# PIC32CM5164JH00032 register map
Vendor: Microchip Technology; Series: PIC32CMJH00; File version: 0
CPU: CM0+ r0p0, little endian, MPU, no FPU, VTOR, 2 interrupt priority bits, 32 interrupts
Registers are 32-bit, read-write, reset 0x0 unless marked. A register's access mark holds for its fields unless they carry their own. Offsets are from the block's base; [hi:lo] are bit positions; {n}, {i} and the like mark numbered series; 'fields as' and 'values as' point back to an identical list.

## OSCCTRL — Oscillators Control
Base 0x40001000
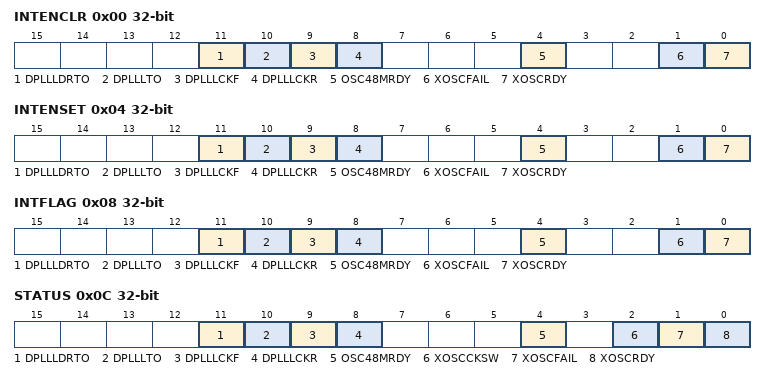
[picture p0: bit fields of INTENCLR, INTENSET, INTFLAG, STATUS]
0x00 INTENCLR write-1-clears — Interrupt Enable Clear
  [11] DPLLLDRTO — DPLL Ratio Ready Interrupt Enable
  [10] DPLLLTO — DPLL Time Out Interrupt Enable
  [9] DPLLLCKF — DPLL Lock Fall Interrupt Enable
  [8] DPLLLCKR — DPLL Lock Rise Interrupt Enable
  [4] OSC48MRDY — OSC48M Ready Interrupt Enable
  [1] XOSCFAIL — XOSC Clock Failure Detector Interrupt Enable
  [0] XOSCRDY — XOSC Ready Interrupt Enable
0x04 INTENSET write-1-sets — Interrupt Enable Set
  fields as INTENCLR
0x08 INTFLAG write-1-clears — Interrupt Flag Status and Clear
  [11] DPLLLDRTO — DPLL Ratio Ready
  [10] DPLLLTO — DPLL Timeout
  [9] DPLLLCKF — DPLL Lock Fall
  [8] DPLLLCKR — DPLL Lock Rise
  [4] OSC48MRDY — OSC48M Ready
  [1] XOSCFAIL — XOSC Clock Failure Detector
  [0] XOSCRDY — XOSC Ready
0x0C STATUS ro — Power and Clocks Status
  [11] DPLLLDRTO — DPLL Ratio Ready
  [10] DPLLLTO — DPLL Timeout
  [9] DPLLLCKF — DPLL Lock Fall
  [8] DPLLLCKR — DPLL Lock Rise
  [4] OSC48MRDY — OSC48M Ready
  [2] XOSCCKSW — XOSC Clock Switch
  [1] XOSCFAIL — XOSC Clock Failure Detector
  [0] XOSCRDY — XOSC Ready
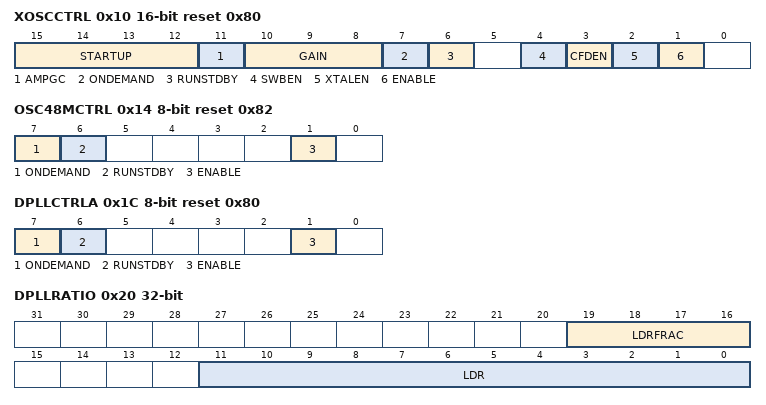
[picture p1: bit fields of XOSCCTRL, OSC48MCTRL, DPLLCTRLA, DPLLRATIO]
0x10 XOSCCTRL 16-bit reset 0x80 — External Multipurpose Crystal Oscillator (XOSC) Control
  [15:12] STARTUP — Start-Up Time
    0=CYCLE1 (1 cycle); 1=CYCLE2 (2 cycles); 2=CYCLE4 (4 cycles); 3=CYCLE8 (8 cycles); 4=CYCLE16 (16 cycles); 5=CYCLE32 (32 cycles); 6=CYCLE64 (64 cycles); 7=CYCLE128 (128 cycles); 8=CYCLE256 (256 cycles); 9=CYCLE512 (512 cycles); 10=CYCLE1024 (1024 cycles); 11=CYCLE2048 (2048 cycles); 12=CYCLE4096 (4096 cycles); 13=CYCLE8192 (8192 cycles); 14=CYCLE16384 (16384 cycles); 15=CYCLE32768 (32768 cycles)
  [11] AMPGC — Automatic Amplitude Gain Control
  [10:8] GAIN — Oscillator Gain
    0=2 MHz; 1=4 MHz; 2=8 MHz; 3=16 MHz; 4=32 MHz
  [7] ONDEMAND — On Demand Control
  [6] RUNSTDBY — Run in Standby
  [4] SWBEN — Clock Switch Back Enable
  [3] CFDEN — Xosc Clock Failure Detector Enable
  [2] XTALEN — Crystal Oscillator Enable
  [1] ENABLE — Oscillator Enable
0x12 CFDPRESC 8-bit — Clock Failure Detector Prescaler
  [2:0] CFDPRESC
    0=DIV1 (OSC48M frequency); 1=DIV2 (OSC48M frequency / 2); 2=DIV4 (OSC48M frequency / 4); 3=DIV8 (OSC48M frequency / 8); 4=DIV16 (OSC48M frequency / 16); 5=DIV32 (OSC48M frequency / 32); 6=DIV64 (OSC48M frequency / 64); 7=DIV128 (OSC48M frequency / 128)
0x13 EVCTRL 8-bit — Event Control
  [0] CFDEO — Clock Failure Detector Event Output Enable
0x14 OSC48MCTRL 8-bit reset 0x82 — 48MHz Internal Oscillator (OSC48M) Control
  [7] ONDEMAND — On Demand Control
  [6] RUNSTDBY — Run in Standby
  [1] ENABLE — Oscillator Enable
0x15 OSC48MDIV 8-bit reset 0xB — OSC48M Divider
  [3:0] DIV — OSC48M Division Factor
    0=48 MHz; 1=24 MHz; 2=16 MHz; 3=12 MHz; 4=9.6 MHz; 5=8 MHz; 6=6.86 MHz; 7=6 MHz; 8=5.33 MHz; 9=4.8 MHz; 10=4.36 MHz; 11=4 MHz; 12=3.69 MHz; 13=3.43 MHz; 14=3.2 MHz; 15=3 MHz
0x16 OSC48MSTUP 8-bit reset 0x7 — OSC48M Startup Time
  [2:0] STARTUP — Startup Time
    0=CYCLE8 (166 ns); 1=CYCLE16 (333 ns); 2=CYCLE32 (667 ns); 3=CYCLE64 (1.333 us); 4=CYCLE128 (2.667 us); 5=CYCLE256 (5.333 us); 6=CYCLE512 (10.667 us); 7=CYCLE1024 (21.333 us)
0x18 OSC48MSYNCBUSY ro — OSC48M Synchronization Busy
  [2] OSC48MDIV — OSC48MDIV Synchronization Status
0x1C DPLLCTRLA 8-bit reset 0x80 — DPLL Control
  [7] ONDEMAND
  [6] RUNSTDBY — Run in Standby
  [1] ENABLE
0x20 DPLLRATIO — DPLL Ratio Control
  [19:16] LDRFRAC — Loop Divider Ratio Fractional Part
  [11:0] LDR — Loop Divider Ratio
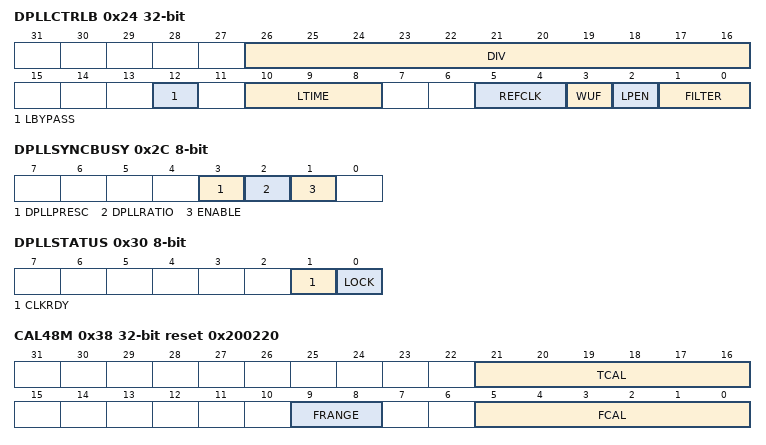
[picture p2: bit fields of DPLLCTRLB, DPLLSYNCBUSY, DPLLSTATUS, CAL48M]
0x24 DPLLCTRLB — Digital Core Configuration
  [26:16] DIV — Clock Divider
  [12] LBYPASS — Lock Bypass
  [10:8] LTIME — Lock Time
    0=Default (No time-out. Automatic lock); {v}={v+4}MS (Time-out if no lock within {v+4} ms) (v=4..7)
  [5:4] REFCLK — Reference Clock Selection
    0=XOSC32K (XOSC32K Clock Reference); 1=XOSC (XOSC Clock Reference); 2=GCLK (GCLK Clock Reference)
  [3] WUF — Wake Up Fast
  [2] LPEN — Low-Power Enable
  [1:0] FILTER — Proportional Integral Filter Selection
    0=Default Filter Mode; 1=LBFILT (Low Bandwidth Filter); 2=HBFILT (High Bandwidth Filter); 3=HDFILT (High Damping Filter)
0x28 DPLLPRESC 8-bit — DPLL Prescaler
  [1:0] PRESC — Output Clock Prescaler
    0=DIV1 (DPLL output is divided by 1); 1=DIV2 (DPLL output is divided by 2); 2=DIV4 (DPLL output is divided by 4)
0x2C DPLLSYNCBUSY 8-bit ro — DPLL Synchronization Busy
  [3] DPLLPRESC — DPLL Prescaler Synchronization Status
  [2] DPLLRATIO — DPLL Ratio Synchronization Status
  [1] ENABLE — DPLL Enable Synchronization Status
0x30 DPLLSTATUS 8-bit ro
  [1] CLKRDY — DPLL Clock Ready
  [0] LOCK — DPLL Lock Status
0x38 CAL48M reset 0x200220 — 48MHz Oscillator Calibration
  [21:16] TCAL — Temperature Calibration (48MHz)
  [9:8] FRANGE — Frequency Range (48MHz)
  [5:0] FCAL — Frequency Calibration (48MHz)

## Notices in the file
Copyright (c) 2026 Microchip Technology Inc.
SPDX-License-Identifier: Apache-2.0
Licensed under the Apache License, Version 2.0 (the "License");
you may not use this file except in compliance with the License.
You may obtain a copy of the License at
http://www.apache.org/licenses/LICENSE-2.0
Unless required by applicable law or agreed to in writing, software
distributed under the License is distributed on an "AS IS" BASIS,
WITHOUT WARRANTIES OR CONDITIONS OF ANY KIND, either express or implied.
See the License for the specific language governing permissions and
limitations under the License.
